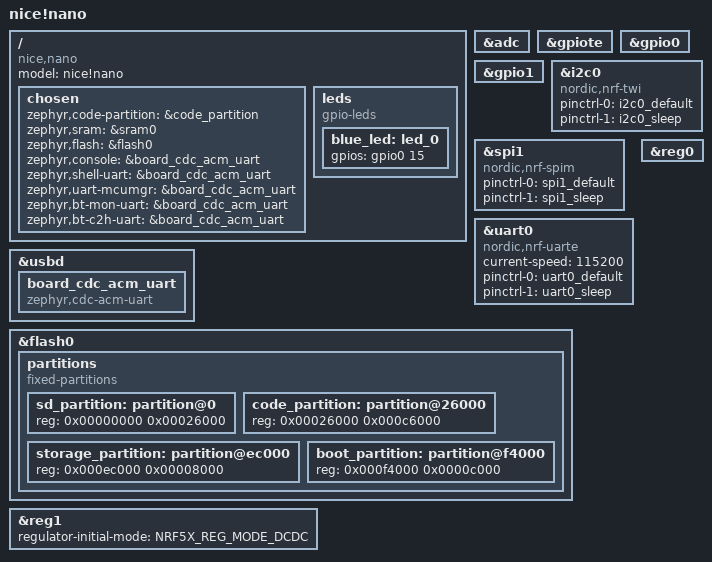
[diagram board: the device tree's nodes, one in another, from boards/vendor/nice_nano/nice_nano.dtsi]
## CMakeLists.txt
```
# SPDX-License-Identifier: Apache-2.0

list(APPEND BOARD_ROOT ${CMAKE_CURRENT_SOURCE_DIR})

cmake_minimum_required(VERSION 3.20.0)
find_package(Zephyr REQUIRED HINTS $ENV{ZEPHYR_BASE})
project(console)

FILE(GLOB app_sources src/*.c)
target_sources(app PRIVATE ${app_sources})
```

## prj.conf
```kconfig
CONFIG_USB_DEVICE_STACK=y
CONFIG_USB_DEVICE_PRODUCT=""
CONFIG_USB_DEVICE_PID=0x0004
CONFIG_USB_DEVICE_INITIALIZE_AT_BOOT=n

CONFIG_SERIAL=y
CONFIG_CONSOLE=y
CONFIG_UART_CONSOLE=y
CONFIG_UART_LINE_CTRL=y
```

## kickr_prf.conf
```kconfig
CONFIG_STDOUT_CONSOLE=y
CONFIG_SERIAL=y
CONFIG_UART_LINE_CTRL=y
CONFIG_USBD_CDC_ACM_CLASS=y

CONFIG_LOG=y
CONFIG_USBD_LOG_LEVEL_WRN=y
CONFIG_UDC_DRIVER_LOG_LEVEL_WRN=y
```

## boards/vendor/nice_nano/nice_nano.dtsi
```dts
/*
 * Copyright (c) 2021 The ZMK Contributors
 *
 * SPDX-License-Identifier: MIT
 */

#include <nordic/nrf52840_qiaa.dtsi>
#include "nice_nano-pinctrl.dtsi"
#include "arduino_pro_micro_pins.dtsi"

/ {
    model = "nice!nano";
    compatible = "nice,nano";

    chosen {
        zephyr,code-partition = &code_partition;
        zephyr,sram = &sram0;
        zephyr,flash = &flash0;
        zephyr,console = &board_cdc_acm_uart;
        zephyr,shell-uart = &board_cdc_acm_uart;
        zephyr,uart-mcumgr = &board_cdc_acm_uart;
        zephyr,bt-mon-uart = &board_cdc_acm_uart;
        zephyr,bt-c2h-uart = &board_cdc_acm_uart;        
    };

    leds {
        compatible = "gpio-leds";
        blue_led: led_0 {
            gpios = <&gpio0 15 GPIO_ACTIVE_HIGH>;
        };
    };
};

&adc {
    status = "okay";
};

&gpiote {
    status = "okay";
};

&gpio0 {
    status = "okay";
};

&gpio1 {
    status = "okay";
};

&i2c0 {
    compatible = "nordic,nrf-twi";
    pinctrl-0 = <&i2c0_default>;
    pinctrl-1 = <&i2c0_sleep>;
    pinctrl-names = "default", "sleep";
};

&spi1 {
    compatible = "nordic,nrf-spim";
    pinctrl-0 = <&spi1_default>;
    pinctrl-1 = <&spi1_sleep>;
    pinctrl-names = "default", "sleep";
};

&uart0 {
    compatible = "nordic,nrf-uarte";
    current-speed = <115200>;
    pinctrl-0 = <&uart0_default>;
    pinctrl-1 = <&uart0_sleep>;
    pinctrl-names = "default", "sleep";
};

zephyr_udc0: &usbd {
    status = "okay";
    board_cdc_acm_uart: board_cdc_acm_uart {
        compatible = "zephyr,cdc-acm-uart";
    };
};

&flash0 {
    /*
     * For more information, see:
     * http://docs.zephyrproject.org/latest/devices/dts/flash_partitions.html
     */
    partitions {
        compatible = "fixed-partitions";
        #address-cells = <1>;
        #size-cells = <1>;

        sd_partition: partition@0 {
            reg = <0x00000000 0x00026000>;
        };
        code_partition: partition@26000 {
            reg = <0x00026000 0x000c6000>;
        };

        /*
         * The flash starting at 0x000ec000 and ending at
         * 0x000f3fff is reserved for use by the application.
         */

        /*
         * Storage partition will be used by FCB/LittleFS/NVS
         * if enabled.
         */
        storage_partition: partition@ec000 {
            reg = <0x000ec000 0x00008000>;
        };

        boot_partition: partition@f4000 {
            reg = <0x000f4000 0x0000c000>;
        };
    };
};

/* configure REG/REG1 in DC/DC mode */
&reg1 {
    regulator-initial-mode = <NRF5X_REG_MODE_DCDC>;
};

/* enable REG0 (HV mode) */
&reg0 {
    status = "okay";
};
```

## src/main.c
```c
#include <zephyr/drivers/gpio.h>
#include <zephyr/drivers/uart.h>
#include <zephyr/kernel.h>
#include <zephyr/sys/printk.h>
#include <zephyr/usb/usb_device.h>
#include <zephyr/usb/usbd.h>

BUILD_ASSERT(DT_NODE_HAS_COMPAT(DT_CHOSEN(zephyr_console), zephyr_cdc_acm_uart),
             "Console device is not ACM CDC UART device");

#define P0_NODE DT_NODELABEL(gpio0)
#define P1_NODE DT_NODELABEL(gpio1)
static const struct device *p0 = DEVICE_DT_GET(P0_NODE);
static const struct device *p1 = DEVICE_DT_GET(P1_NODE);
static struct gpio_callback cb_data;

void callback(const struct device *dev, struct gpio_callback *cb,
              uint32_t pins) {
  int v = gpio_pin_get(p0, 6);
  printk("Callback at %d %d\n", pins, v);
}

int main(void) {
  const struct device *const dev = DEVICE_DT_GET(DT_CHOSEN(zephyr_console));
  uint32_t dtr = 0;

  if (usb_enable(NULL)) {
    return 0;
  }

  if (!device_is_ready(p0)) {
    return 0;
  }

  if (!device_is_ready(p1)) {
    return 0;
  }

  if (gpio_pin_configure(p0, 15, GPIO_OUTPUT_ACTIVE) < 0) {
    return 0;
  }

  int p0_pins[] = {2, 6, 8, 9, 10, 11, 17, 20, 22, 24, 29, 31};
  int p1_pins[] = {0, 1, 2, 4, 6, 7, 11, 13, 15};

  for (int i = 0; i < 12; i++) {
    if (gpio_pin_configure(p0, p0_pins[i], GPIO_INPUT) < 0) {
      return 0;
    }
  }

  for (int i = 0; i < 9; i++) {
    if (gpio_pin_configure(p1, p1_pins[i], GPIO_INPUT) < 0) {
      return 0;
    }
  }

  if (gpio_pin_interrupt_configure(p0, 6, GPIO_INT_EDGE_BOTH) < 0) {
    return 0;
  }

  gpio_init_callback(&cb_data, callback, BIT(6));
  gpio_add_callback(p0, &cb_data);

  /* Poll if the DTR flag was set */
  while (!dtr) {
    uart_line_ctrl_get(dev, UART_LINE_CTRL_DTR, &dtr);
    /* Give CPU resources to low priority threads. */
    k_sleep(K_MSEC(100));
  }

  while (1) {
    printk("Hello World! %s\n", CONFIG_ARCH);
    if (gpio_pin_toggle(p0, 15) < 0) {
      return 0;
    }
    printk("p0: ");
    for (int i = 0; i < 12; i++) {
      int v = gpio_pin_get(p0, p0_pins[i]);
      printk("%d", v);
    }
    printk("\n");
    printk("p1: ");
    for (int i = 0; i < 9; i++) {
      int v = gpio_pin_get(p1, p1_pins[i]);
      printk("%d", v);
    }
    printk("\n");
    k_sleep(K_SECONDS(1));
  }
}
```
